AUTOSAR XML (schema 314)
package /ComponentType
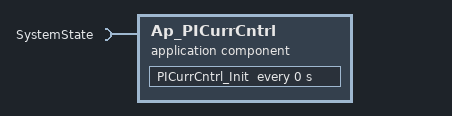
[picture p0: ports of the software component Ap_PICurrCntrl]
  application software component type Ap_PICurrCntrl
    require port SystemState: required-interface=SystemState
  internal behavior Ap_PICurrCntrl_InternalBehavior: component=Ap_PICurrCntrl, port-api-option{enable-take-address=false, indirect-api=false, port=SystemState}
    timing event PICurrCntrl_InitEvent: start-on-event=PICurrCntrl_Init, period=0
    runnable PICurrCntrl_Init
  swc implementation Ap_PICurrCntrl_Implementation: behavior=Ap_PICurrCntrl_InternalBehavior
    code-descriptors:
      code Code: type=SRC
